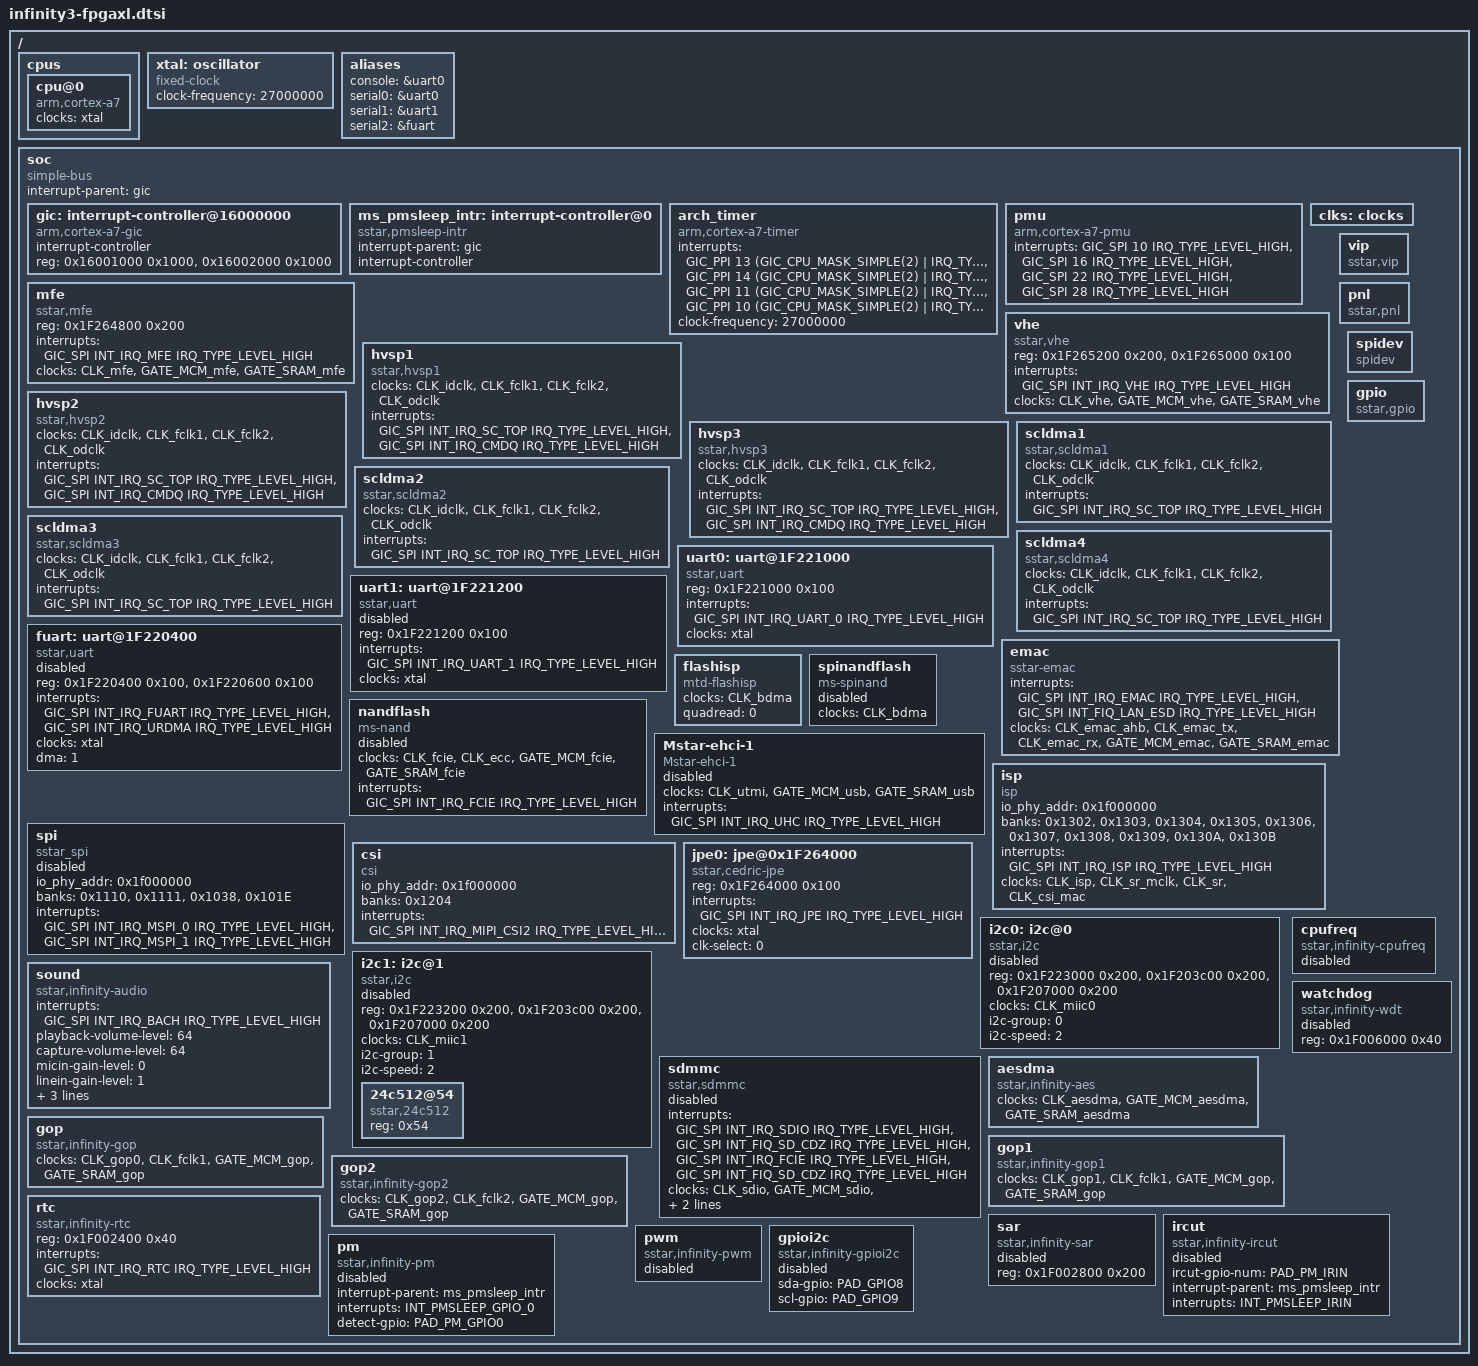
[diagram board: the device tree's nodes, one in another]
/*
* infinity3-fpgaxl.dtsi- Sigmastar
*
* Copyright (c) [2019~2020] SigmaStar Technology.
*
*
* This software is licensed under the terms of the GNU General Public
* License version 2, as published by the Free Software Foundation, and
* may be copied, distributed, and modified under those terms.
*
* This program is distributed in the hope that it will be useful,
* but WITHOUT ANY WARRANTY; without even the implied warranty of
* MERCHANTABILITY or FITNESS FOR A PARTICULAR PURPOSE.  See the
* GNU General Public License version 2 for more details.
*
*/

#include <../../../../drivers/sstar/include/infinity3/irqs.h>
#include <../../../../drivers/sstar/include/infinity3/gpio.h>
#include <dt-bindings/interrupt-controller/irq.h>
#include <dt-bindings/interrupt-controller/arm-gic.h>
#include "skeleton.dtsi"


/ {
    cpus {
        #address-cells = <1>;
        #size-cells = <0>;

        cpu@0 {
            device_type = "cpu";
            compatible = "arm,cortex-a7";
            clocks = <&xtal>;
        };
    };

    xtal: oscillator {
        compatible = "fixed-clock";
        #clock-cells = <0>;
        clock-frequency = <27000000>;
    };

    aliases {
        console = &uart0;
        serial0 = &uart0;
        serial1 = &uart1;
        serial2 = &fuart;
    };

    soc {
        compatible = "simple-bus";
        interrupt-parent = <&gic>;
        #address-cells = <1>;
        #size-cells = <1>;
        ranges;

        gic: interrupt-controller@16000000 {
            compatible = "arm,cortex-a7-gic";
            #interrupt-cells = <3>;
            #address-cells = <1>;
            #size-cells = <1>;
            interrupt-controller;
            reg = <0x16001000 0x1000>,
                  <0x16002000 0x1000>;
        };

        ms_pmsleep_intr: interrupt-controller@0 {
            compatible = "sstar,pmsleep-intr";
            #interrupt-cells = <1>;
            interrupt-parent=<&gic>;
            interrupt-controller;
        };


        arch_timer {
            compatible = "arm,cortex-a7-timer", "arm,armv7-timer";
            interrupts = <GIC_PPI 13 (GIC_CPU_MASK_SIMPLE(2) | IRQ_TYPE_LEVEL_LOW)>,
                         <GIC_PPI 14 (GIC_CPU_MASK_SIMPLE(2) | IRQ_TYPE_LEVEL_LOW)>,
                         <GIC_PPI 11 (GIC_CPU_MASK_SIMPLE(2) | IRQ_TYPE_LEVEL_LOW)>,
                         <GIC_PPI 10 (GIC_CPU_MASK_SIMPLE(2) | IRQ_TYPE_LEVEL_LOW)>;
            clock-frequency = <27000000>;  /* arch_timer must use clock-frequency*/
        };

        pmu {
            compatible = "arm,cortex-a7-pmu";
            interrupts = <GIC_SPI 10 IRQ_TYPE_LEVEL_HIGH>,
                         <GIC_SPI 16 IRQ_TYPE_LEVEL_HIGH>,
                         <GIC_SPI 22 IRQ_TYPE_LEVEL_HIGH>,
                         <GIC_SPI 28 IRQ_TYPE_LEVEL_HIGH>;
        };

        clks: clocks{
            #address-cells = <1>;
            #size-cells = <1>;
            ranges;
        };

/*
        timer_clockevent: timer@1F006040 {
            compatible = "sstar,piu-clockevent";
            reg = <0x1F006040 0x100>;
            interrupts=<GIC_SPI INT_FIQ_TIMER_0 IRQ_TYPE_LEVEL_HIGH>;
            clocks = <&CLK_xtali_12m>;
        };
*/
        mfe: mfe {
            compatible = "sstar,mfe";
            reg = <0x1F264800 0x200>;
            interrupts=<GIC_SPI INT_IRQ_MFE IRQ_TYPE_LEVEL_HIGH>;
            clocks = <&CLK_mfe>,<&GATE_MCM_mfe>, <&GATE_SRAM_mfe>;
            clock-names = "CKG_mfe";
            status = "ok";
        };

        vhe: vhe {
            compatible = "sstar,vhe";
            reg = <0x1F265200 0x200>,<0x1F265000 0x100>;
            interrupts=<GIC_SPI INT_IRQ_VHE IRQ_TYPE_LEVEL_HIGH>;
            clocks = <&CLK_vhe>,<&GATE_MCM_vhe>, <&GATE_SRAM_vhe>;
            clock-names = "CKG_vhe";
            status = "ok";
        };

        hvsp1: hvsp1 {
            compatible = "sstar,hvsp1";
            //reg = <0x1F000000 0x100>;
            //clk,chiptop,hvsp0,sc0,dnr,ldc
            clocks = <&CLK_idclk>,<&CLK_fclk1>,<&CLK_fclk2>,<&CLK_odclk>;
            clock-names = "CLK_idclk","CLK_fclk1","CLK_fclk2","CLK_odclk";
            status = "ok";
            interrupts = <GIC_SPI INT_IRQ_SC_TOP IRQ_TYPE_LEVEL_HIGH>, <GIC_SPI INT_IRQ_CMDQ IRQ_TYPE_LEVEL_HIGH>;
        };

        hvsp2: hvsp2 {
            compatible = "sstar,hvsp2";
            //reg = <0x1F000000 0x100>;
            //clk,chiptop,hvsp0,sc0,dnr,ldc
            clocks = <&CLK_idclk>,<&CLK_fclk1>,<&CLK_fclk2>,<&CLK_odclk>;
            clock-names = "CLK_idclk","CLK_fclk1","CLK_fclk2","CLK_odclk";
            status = "ok";
            interrupts = <GIC_SPI INT_IRQ_SC_TOP IRQ_TYPE_LEVEL_HIGH>, <GIC_SPI INT_IRQ_CMDQ IRQ_TYPE_LEVEL_HIGH>;
        };

        hvsp3: hvsp3 {
            compatible = "sstar,hvsp3";
            //reg = <0x1F000000 0x100>;
            //clk,chiptop,hvsp0,sc0,dnr,ldc
            clocks = <&CLK_idclk>,<&CLK_fclk1>,<&CLK_fclk2>,<&CLK_odclk>;
            clock-names = "CLK_idclk","CLK_fclk1","CLK_fclk2","CLK_odclk";
            status = "ok";
            interrupts = <GIC_SPI INT_IRQ_SC_TOP IRQ_TYPE_LEVEL_HIGH>, <GIC_SPI INT_IRQ_CMDQ IRQ_TYPE_LEVEL_HIGH>;
        };

        scldma1: scldma1 {
            compatible = "sstar,scldma1";
            //reg = <0x1F000000 0x100>;
            //clk,chiptop,scldma
            clocks =  <&CLK_idclk>,<&CLK_fclk1>,<&CLK_fclk2>,<&CLK_odclk>;
            clock-names = "CLK_idclk","CLK_fclk1","CLK_fclk2","CLK_odclk";
            status = "ok";
            interrupts = <GIC_SPI INT_IRQ_SC_TOP IRQ_TYPE_LEVEL_HIGH>;
        };
        scldma2: scldma2 {
            compatible = "sstar,scldma2";
            //reg = <0x1F000000 0x100>;
            //clk,chiptop,scldma
            clocks =  <&CLK_idclk>,<&CLK_fclk1>,<&CLK_fclk2>,<&CLK_odclk>;
            clock-names = "CLK_idclk","CLK_fclk1","CLK_fclk2","CLK_odclk";
            status = "ok";
            interrupts = <GIC_SPI INT_IRQ_SC_TOP IRQ_TYPE_LEVEL_HIGH>;
        };
        scldma3: scldma3 {
            compatible = "sstar,scldma3";
            //reg = <0x1F000000 0x100>;
            //clk,chiptop,scldma
            clocks =  <&CLK_idclk>,<&CLK_fclk1>,<&CLK_fclk2>,<&CLK_odclk>;
            clock-names = "CLK_idclk","CLK_fclk1","CLK_fclk2","CLK_odclk";
            status = "ok";
            interrupts = <GIC_SPI INT_IRQ_SC_TOP IRQ_TYPE_LEVEL_HIGH>;
        };
        scldma4: scldma4 {
            compatible = "sstar,scldma4";
            //reg = <0x1F000000 0x100>;
            //clk,chiptop,scldma
            clocks =  <&CLK_idclk>,<&CLK_fclk1>,<&CLK_fclk2>,<&CLK_odclk>;
            clock-names = "CLK_idclk","CLK_fclk1","CLK_fclk2","CLK_odclk";
            status = "ok";
            interrupts = <GIC_SPI INT_IRQ_SC_TOP IRQ_TYPE_LEVEL_HIGH>;
        };

        vip: vip {
            compatible = "sstar,vip";
            status = "ok";

            //reg = <0x1F224000 0x200>;
        };

        pnl: pnl {
            compatible = "sstar,pnl";
            status = "ok";

            //Reg = <0x1F224000 0x200>;
        };

        uart0: uart@1F221000 {
            compatible = "sstar,uart";
            reg = <0x1F221000 0x100>;
            interrupts = <GIC_SPI INT_IRQ_UART_0 IRQ_TYPE_LEVEL_HIGH>;
            clocks = <&xtal>;
            status = "ok";
        };
        uart1: uart@1F221200 {
            compatible = "sstar,uart";
            reg = <0x1F221200 0x100>;
            interrupts = <GIC_SPI INT_IRQ_UART_1 IRQ_TYPE_LEVEL_HIGH>;
            clocks = <&xtal>;
            status = "disabled";
        };
        fuart: uart@1F220400 {
            compatible = "sstar,uart";
            reg = <0x1F220400 0x100>, <0x1F220600 0x100>;
            interrupts = <GIC_SPI INT_IRQ_FUART IRQ_TYPE_LEVEL_HIGH>, <GIC_SPI INT_IRQ_URDMA IRQ_TYPE_LEVEL_HIGH>;
            clocks = <&xtal>;
            dma = <1>;
            status = "disabled";
        };

        emac {
            compatible = "sstar-emac";
            interrupts = <GIC_SPI INT_IRQ_EMAC IRQ_TYPE_LEVEL_HIGH>, <GIC_SPI INT_FIQ_LAN_ESD IRQ_TYPE_LEVEL_HIGH>;
            clocks = <&CLK_emac_ahb>,<&CLK_emac_tx>,<&CLK_emac_rx>,<&GATE_MCM_emac>, <&GATE_SRAM_emac>;
        };

        flashisp {
            compatible = "mtd-flashisp";
            clocks = <&CLK_bdma>;
            quadread = <0>;
            status = "ok";
        };

        nandflash {
            compatible = "ms-nand";
            clocks =<&CLK_fcie>, <&CLK_ecc>, <&GATE_MCM_fcie>, <&GATE_SRAM_fcie>;
            interrupts =  <GIC_SPI INT_IRQ_FCIE IRQ_TYPE_LEVEL_HIGH>;
            status = "disabled";
        };

        spinandflash {
            compatible = "ms-spinand";
            clocks =<&CLK_bdma>;
			status = "disabled";
        };

        Mstar-ehci-1 {
            compatible = "Mstar-ehci-1";
            clocks = <&CLK_utmi>, <&GATE_MCM_usb>, <&GATE_SRAM_usb>;
            interrupts = <GIC_SPI INT_IRQ_UHC IRQ_TYPE_LEVEL_HIGH>;
			status = "disabled";
        };

        isp: isp {
            compatible = "isp";
            io_phy_addr = <0x1f000000>;
            banks = <0x1302>,<0x1303>,<0x1304>,<0x1305>,<0x1306>,<0x1307>,<0x1308>,<0x1309>,<0x130A>,<0x130B>;
            interrupts = <GIC_SPI INT_IRQ_ISP IRQ_TYPE_LEVEL_HIGH>;
            clocks = <&CLK_isp>,<&CLK_sr_mclk>,<&CLK_sr>,<&CLK_csi_mac>;
            status = "ok";
        };
        spi: spi {
            compatible = "sstar_spi";
            io_phy_addr = <0x1f000000>;
            banks = <0x1110>,<0x1111>,<0x1038>,<0x101E>;
            interrupts = <GIC_SPI INT_IRQ_MSPI_0 IRQ_TYPE_LEVEL_HIGH>,<GIC_SPI INT_IRQ_MSPI_1 IRQ_TYPE_LEVEL_HIGH>;
			status = "disabled";
        };
        spidev: spidev {
            compatible = "spidev";
        };
        csi: csi {
            compatible = "csi";
            io_phy_addr = <0x1f000000>;
            banks = <0x1204>;
            interrupts = <GIC_SPI INT_IRQ_MIPI_CSI2 IRQ_TYPE_LEVEL_HIGH>;
            status = "ok";
        };

        jpe0: jpe@0x1F264000 {
            compatible = "sstar,cedric-jpe";
            reg = <0x1F264000 0x100>;
            interrupts = <GIC_SPI INT_IRQ_JPE IRQ_TYPE_LEVEL_HIGH>;
            clocks = <&xtal>;
            clock-names = "CKG_jpe";
            clk-select = <0>; // 0: 288MHz  1: 216MHz  2: 54MHz  3: 27MHz
            status = "ok";
        };

        i2c0: i2c@0{
            compatible = "sstar,i2c";
            reg = <0x1F223000 0x200>,<0x1F203c00 0x200>,<0x1F207000 0x200>;
                #address-cells = <1>;
                #size-cells = <0>;
            clocks = <&CLK_miic0>;
            i2c-group = <0>;
            i2c-speed = <2>;//0~6
            status = "disabled";
        };

        i2c1: i2c@1{
            compatible = "sstar,i2c";
            reg = <0x1F223200 0x200>,<0x1F203c00 0x200>,<0x1F207000 0x200>;
                #address-cells = <1>;
                #size-cells = <0>;
            clocks = <&CLK_miic1>;
            i2c-group = <1>;
            i2c-speed = <2>;//0~6
            status = "disabled";
              24c512@54 {
            compatible = "sstar,24c512";
            reg = <0x54>;
            };
        };

        gpio:gpio{
            compatible = "sstar,gpio";
        };

        sound {
            compatible = "sstar,infinity-audio";
//            reg = <0x1F000000 0x1000000>;
            interrupts=<GIC_SPI INT_IRQ_BACH IRQ_TYPE_LEVEL_HIGH>;
            playback-volume-level=<64>;    //0~76
            capture-volume-level=<64>;
            micin-gain-level=<0>;    //0~5
            linein-gain-level=<1>;//0~6
            lineout-gain-level=<1>;//0~2
			clocks = <&CLK_utmi>, <&GATE_MCM_bach>, <&GATE_SRAM_bach>;
        };

        sdmmc {
            compatible = "sstar,sdmmc";
            interrupts=<GIC_SPI INT_IRQ_SDIO IRQ_TYPE_LEVEL_HIGH>,
                       <GIC_SPI INT_FIQ_SD_CDZ IRQ_TYPE_LEVEL_HIGH>,
                       <GIC_SPI INT_IRQ_FCIE IRQ_TYPE_LEVEL_HIGH>,
                       <GIC_SPI INT_FIQ_SD_CDZ IRQ_TYPE_LEVEL_HIGH>;
                       //<mie1>,<cdz1>,<mie2, cdz2>....  fice1->fice2->fice3 setting
            clocks = <&CLK_sdio>,<&GATE_MCM_sdio>,<&GATE_SRAM_sdio>,<&CLK_fcie>,<&GATE_MCM_fcie>,<&GATE_SRAM_fcie>;
			status = "disabled";
        };

        aesdma {
            compatible = "sstar,infinity-aes";
            clocks = <&CLK_aesdma>,<&GATE_MCM_aesdma>, <&GATE_SRAM_aesdma>;
        };

        gop{
            compatible = "sstar,infinity-gop";
            clocks = <&CLK_gop0>,<&CLK_fclk1>,<&GATE_MCM_gop>, <&GATE_SRAM_gop>;
            status = "ok";
        };

        gop1{
            compatible = "sstar,infinity-gop1";
            clocks = <&CLK_gop1>,<&CLK_fclk1>,<&GATE_MCM_gop>, <&GATE_SRAM_gop>;
            status = "ok";
        };

        gop2{
            compatible = "sstar,infinity-gop2";
            clocks = <&CLK_gop2>,<&CLK_fclk2>,<&GATE_MCM_gop>, <&GATE_SRAM_gop>;
            status = "ok";
        };
        rtc {
            compatible = "sstar,infinity-rtc";
            reg = <0x1F002400 0x40>;
            interrupts=<GIC_SPI INT_IRQ_RTC IRQ_TYPE_LEVEL_HIGH>;
            clocks =  <&xtal>;
        };

        cpufreq {
            compatible = "sstar,infinity-cpufreq";
			status = "disabled";
        };

        watchdog: watchdog {
            compatible = "sstar,infinity-wdt";
            reg = <0x1F006000 0x40>;
			status = "disabled";
        };

        sar: sar {
            compatible = "sstar,infinity-sar";
            reg = <0x1F002800 0x200>;
			status = "disabled";
        };

        ircut {
            compatible = "sstar,infinity-ircut";
            ircut-gpio-num = <PAD_PM_IRIN>;///PM_GPIO_IRIN
            interrupt-parent = <&ms_pmsleep_intr>;
            interrupts = <INT_PMSLEEP_IRIN>;
			status = "disabled";
        };

        pwm {
            compatible = "sstar,infinity-pwm";
			status = "disabled";
        };

        gpioi2c {
            compatible = "sstar,infinity-gpioi2c";
            sda-gpio = <PAD_GPIO8>;
            scl-gpio = <PAD_GPIO9>;
			status = "disabled";
        };

        pm {
            compatible = "sstar,infinity-pm";
            interrupt-parent = <&ms_pmsleep_intr>;
            interrupts = <INT_PMSLEEP_GPIO_0>;
            detect-gpio = <PAD_PM_GPIO0>;
			status = "disabled";
        };
    };
};

&clks {
    #include <../../../../drivers/sstar/include/infinity3/reg_clks.h>
    #include "infinity3-clks.dtsi"
    #include "infinity3-gates.dtsi"
};
